VERSION ""

NS_ :

BS_:

BU_: XXX

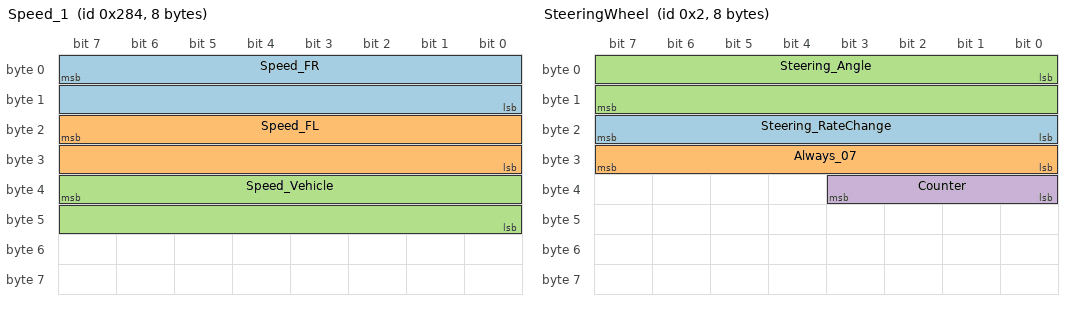
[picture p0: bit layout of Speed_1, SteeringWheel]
BO_ 644 Speed_1: 8 XXX
 SG_ Speed_FR : 7|16@0+ (0.0118,0) [0|65535] "" XXX
 SG_ Speed_FL : 23|16@0+ (0.0118,0) [0|65535] "" XXX
 SG_ Speed_Vehicle : 39|16@0+ (0.0245,0) [0|65535] "" XXX

BO_ 645 WheelspeedRear: 8 XXX
 SG_ RR : 7|16@0+ (0.00555,0) [0|65535] "KPH" XXX
 SG_ RL : 23|16@0+ (0.00555,0) [0|65535] "KPH" XXX

BO_ 768 STEER_TORQUE: 2 XXX
 SG_ STEERING_TORQUE : 6|7@0+ (1,0) [0|127] "" XXX
 SG_ DriverTouchingWheel : 15|1@0+ (-1,1) [0|7] "" XXX

BO_ 459 Maybe_RegenBraking: 8 XXX

BO_ 372 Maybe_Gear_Selector: 8 XXX
 SG_ Counter : 35|4@0+ (1,0) [0|15] "" XXX

BO_ 374 Maybe_Motor_RPM_or_Speed: 8 XXX
 SG_ Counter : 51|4@0+ (1,0) [0|15] "" XXX

BO_ 460 Maybe_Brake_Related: 8 XXX

BO_ 2 SteeringWheel: 8 XXX
 SG_ Steering_RateChange : 16|8@1+ (1,0) [0|255] "" XXX
 SG_ Always_07 : 24|8@1+ (1,0) [0|255] "" XXX
 SG_ Steering_Angle : 0|16@1- (-0.1,0) [0|65535] "" XXX
 SG_ Counter : 32|4@1+ (1,0) [0|15] "" XXX

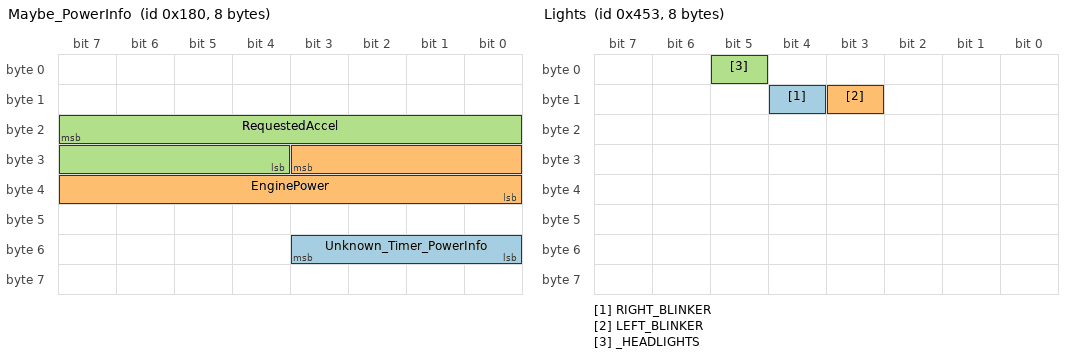
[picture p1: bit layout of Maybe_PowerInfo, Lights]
BO_ 384 Maybe_PowerInfo: 8 XXX
 SG_ Unknown_Timer_PowerInfo : 51|4@0+ (1,0) [0|15] "" XXX
 SG_ EnginePower : 27|12@0- (1,0) [0|1] "" XXX
 SG_ RequestedAccel : 23|12@0- (1,0) [0|4294967295] "" XXX

BO_ 1107 Lights: 8 XXX
 SG_ RIGHT_BLINKER : 12|1@0+ (1,0) [0|1] "" XXX
 SG_ LEFT_BLINKER : 11|1@0+ (1,0) [0|1] "" XXX
 SG_ _HEADLIGHTS : 5|1@0+ (1,0) [0|1] "" XXX

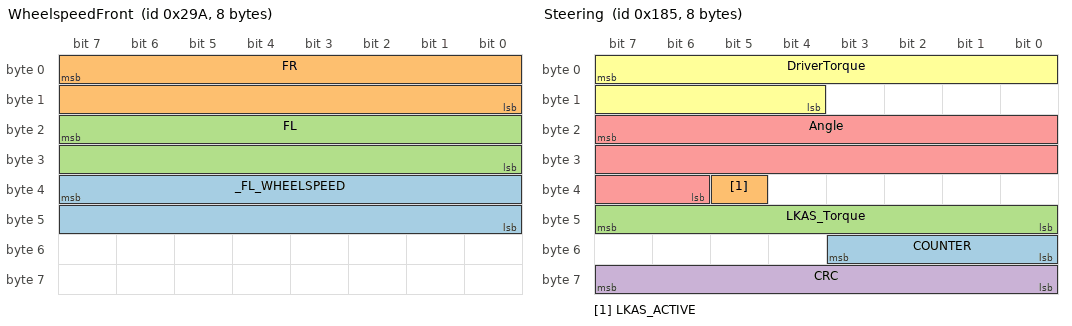
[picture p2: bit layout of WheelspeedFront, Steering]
BO_ 666 WheelspeedFront: 8 XXX
 SG_ _FL_WHEELSPEED : 39|16@0+ (0.01014,0) [0|65535] "" XXX
 SG_ FR : 7|16@0+ (0.00555,0) [0|65535] "KPH" XXX
 SG_ FL : 23|16@0+ (0.00555,0) [0|65535] "KPH" XXX

BO_ 389 Steering: 8 XXX
 SG_ COUNTER : 51|4@0+ (1,0) [0|15] "" XXX
 SG_ LKAS_ACTIVE : 37|1@0+ (1,0) [0|3] "" XXX
 SG_ LKAS_Torque : 47|8@0+ (1,0) [0|255] "" XXX
 SG_ CRC : 63|8@0+ (1,0) [0|127] "" XXX
 SG_ Angle : 23|18@0+ (-0.01,1310) [0|262143] "" XXX
 SG_ DriverTorque : 7|12@0+ (-0.01,20.47) [0|4095] "Nm" XXX

BO_ 851 SPEED_RELATED: 8 XXX
 SG_ SPEED_RELATED : 7|16@0+ (0.01014,0) [0|65535] "" XXX

BO_ 386 Accelerator: 8 XXX
 SG_ Accelerator : 38|7@0+ (1,0) [0|127] "" XXX

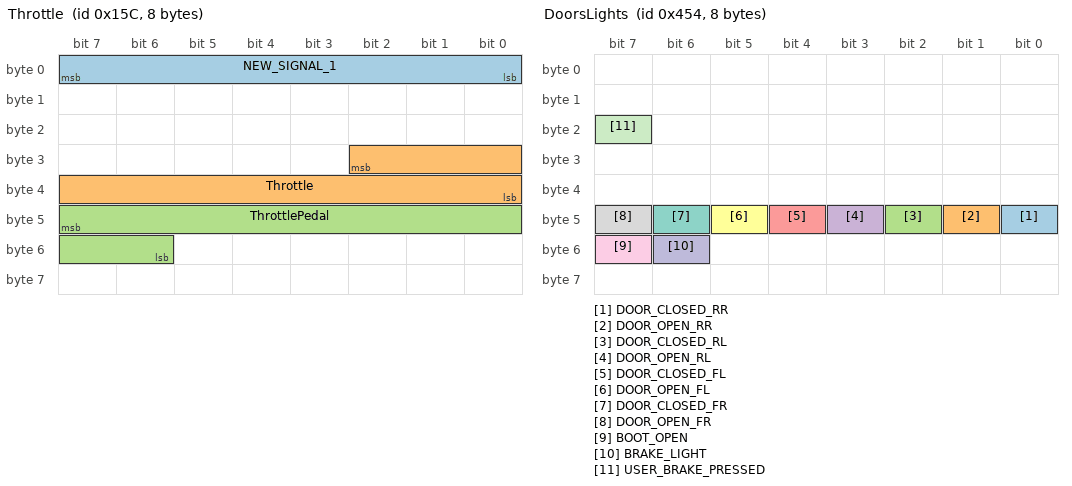
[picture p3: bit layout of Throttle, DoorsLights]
BO_ 348 Throttle: 8 XXX
 SG_ NEW_SIGNAL_1 : 7|8@0+ (1,0) [0|255] "" XXX
 SG_ Throttle : 26|11@0+ (1,0) [0|2047] "" XXX
 SG_ ThrottlePedal : 47|10@0+ (1,0) [0|1023] "" XXX

BO_ 523 CruiseThrottle: 6 XXX
 SG_ PROPILOT_BUTTON : 8|1@0+ (1,0) [0|1] "" XXX
 SG_ CANCEL_BUTTON : 9|1@0+ (1,0) [0|1] "" XXX
 SG_ GAS_PEDAL_INVERTED : 37|10@0+ (1,0) [0|1023] "" XXX
 SG_ SET_BUTTON : 11|1@0+ (1,0) [0|1] "" XXX
 SG_ RES_BUTTON : 12|1@0+ (1,0) [0|1] "" XXX
 SG_ FOLLOW_DISTANCE_BUTTON : 10|1@0+ (1,0) [0|1] "" XXX
 SG_ NO_BUTTON_PRESSED : 13|1@0+ (1,0) [0|1] "" XXX
 SG_ GAS_PEDAL : 31|10@0+ (1,0) [0|255] "" XXX
 SG_ USER_BRAKE_PRESSED : 21|1@0+ (1,0) [0|1] "" XXX
 SG_ USER_BRAKE_PRESSED_INVERTED : 22|1@0+ (1,0) [0|3] "" XXX
 SG_ NEW_SIGNAL_2 : 23|1@0+ (1,0) [0|1] "" XXX
 SG_ unsure2 : 43|4@0+ (1,0) [0|1] "" XXX
 SG_ unsure1 : 7|16@0+ (1,0) [0|15] "" XXX
 SG_ GAS_PRESSED_INVERTED : 20|1@0+ (1,0) [0|255] "" XXX
 SG_ COUNTER : 17|2@0+ (1,0) [0|3] "" XXX
 SG_ unsure3 : 19|2@0+ (1,0) [0|3] "" XXX

BO_ 1108 DoorsLights: 8 XXX
 SG_ DOOR_CLOSED_RR : 40|1@0+ (1,0) [0|1] "" XXX
 SG_ DOOR_OPEN_RR : 41|1@0+ (1,0) [0|1] "" XXX
 SG_ DOOR_CLOSED_RL : 42|1@0+ (1,0) [0|1] "" XXX
 SG_ DOOR_OPEN_RL : 43|1@0+ (1,0) [0|1] "" XXX
 SG_ DOOR_CLOSED_FL : 44|1@0+ (1,0) [0|1] "" XXX
 SG_ DOOR_OPEN_FL : 45|1@0+ (1,0) [0|1] "" XXX
 SG_ DOOR_CLOSED_FR : 46|1@0+ (1,0) [0|3] "" XXX
 SG_ DOOR_OPEN_FR : 47|1@0+ (1,0) [0|3] "" XXX
 SG_ BOOT_OPEN : 55|1@0+ (1,0) [0|1] "" XXX
 SG_ BRAKE_LIGHT : 54|1@0+ (1,0) [0|1] "" XXX
 SG_ USER_BRAKE_PRESSED : 23|1@0+ (1,0) [0|1] "" XXX

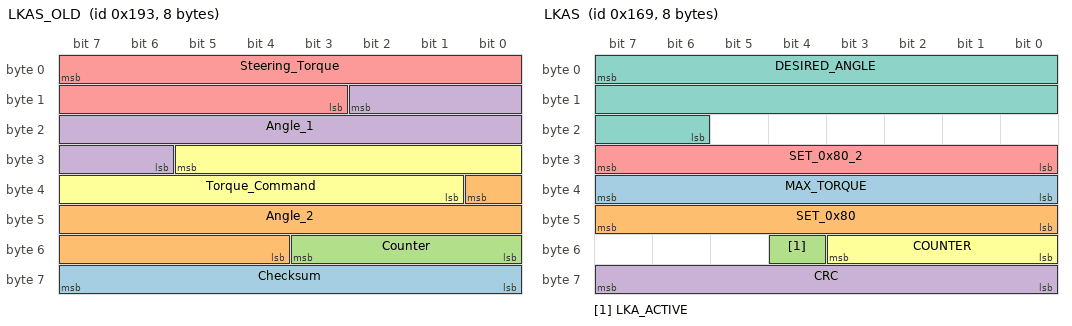
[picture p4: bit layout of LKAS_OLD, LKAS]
BO_ 403 LKAS_OLD: 8 XXX
 SG_ Checksum : 63|8@0+ (1,0) [0|255] "" XXX
 SG_ Angle_2 : 32|13@0+ (1,-4000) [0|63] "" XXX
 SG_ Counter : 51|4@0+ (1,0) [0|15] "" XXX
 SG_ Angle_1 : 10|13@0+ (0.12,-480) [0|65535] "" XXX
 SG_ Steering_Torque : 7|13@0+ (-1,4000) [0|65535] "" XXX
 SG_ Torque_Command : 29|13@0+ (1,-4000) [0|255] "" XXX

BO_ 361 LKAS: 8 XXX
 SG_ MAX_TORQUE : 39|8@0+ (0.01,0) [0|255] "Nm" XXX
 SG_ SET_0x80 : 47|8@0+ (1,0) [0|255] "" XXX
 SG_ LKA_ACTIVE : 52|1@0+ (1,0) [0|15] "" XXX
 SG_ CRC : 63|8@0+ (1,0) [0|255] "" XXX
 SG_ SET_0x80_2 : 31|8@0+ (1,0) [0|255] "" XXX
 SG_ COUNTER : 51|4@0+ (1,0) [0|15] "" XXX
 SG_ DESIRED_ANGLE : 7|18@0+ (-0.01,1310) [0|255] "" XXX

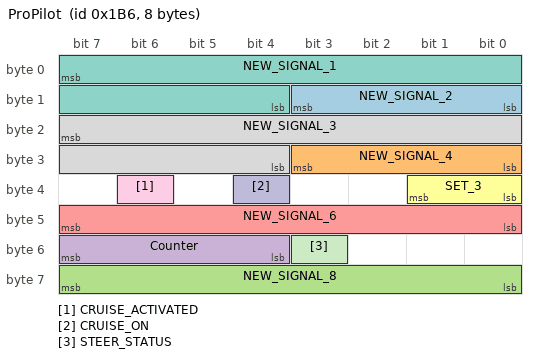
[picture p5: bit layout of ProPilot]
BO_ 438 ProPilot: 8 XXX
 SG_ NEW_SIGNAL_2 : 11|4@0+ (1,0) [0|255] "" XXX
 SG_ NEW_SIGNAL_4 : 27|4@0+ (1,0) [0|255] "" XXX
 SG_ NEW_SIGNAL_8 : 63|8@0+ (1,0) [0|7] "" XXX
 SG_ Counter : 55|4@0+ (1,0) [0|255] "" XXX
 SG_ NEW_SIGNAL_6 : 47|8@0+ (1,0) [0|255] "" XXX
 SG_ SET_3 : 33|2@0+ (1,0) [0|15] "" XXX
 SG_ NEW_SIGNAL_1 : 7|12@0- (1,0) [0|255] "" XXX
 SG_ NEW_SIGNAL_3 : 23|12@0- (-1,0) [0|255] "" XXX
 SG_ CRUISE_ACTIVATED : 38|1@0+ (1,0) [0|3] "" XXX
 SG_ CRUISE_ON : 36|1@0+ (1,0) [0|255] "" XXX
 SG_ STEER_STATUS : 51|1@0+ (1,0) [0|3] "" XXX

BO_ 397 _GEAR: 8 XXX
 SG_ GEAR : 27|4@0+ (1,0) [0|15] "" XXX

BO_ 1273 _SEATBELT: 7 XXX
 SG_ DRIVERS_SEATBELT : 25|1@0+ (1,0) [0|1] "" XXX

BO_ 665 _ESP: 8 XXX
 SG_ ESP_DISABLED : 24|1@0+ (1,0) [0|1] "" XXX

BO_ 1055 GEARBOX: 2 XXX
 SG_ SPORTS_MODE : 13|1@0+ (1,0) [0|1] "" XXX
 SG_ GEAR_SHIFTER : 5|3@0+ (1,0) [0|255] "" XXX

BO_ 1228 PROPILOT_HUD_INFO_MSG: 8 XXX
 SG_ NA_HIGH_ACCEL_TEMP : 0|1@0+ (1,0) [0|1] "" XXX
 SG_ SIDE_RADAR_NA_HIGH_CABIN_TEMP : 8|1@0+ (1,0) [0|1] "" XXX
 SG_ SIDE_RADAR_MALFUNCTION : 11|1@0+ (1,0) [0|1] "" XXX
 SG_ LKAS_MALFUNCTION : 12|1@0+ (1,0) [0|1] "" XXX
 SG_ FRONT_RADAR_MALFUNCTION : 13|1@0+ (1,0) [0|1] "" XXX
 SG_ SIDE_RADAR_NA_CLEAN_REAR_CAMERA : 14|1@0+ (1,0) [0|1] "" XXX
 SG_ NA_POOR_ROAD_CONDITIONS : 16|1@0+ (1,0) [0|1] "" XXX
 SG_ CURRENTLY_UNAVAILABLE : 17|1@0+ (1,0) [0|1] "" XXX
 SG_ SAFETY_SHIELD_OFF : 18|1@0+ (1,0) [0|1] "" XXX
 SG_ FRONT_COLLISION_NA_FRONT_RADAR_OBSTRUCTION : 20|1@0+ (1,0) [0|1] "" XXX
 SG_ PEDAL_MISSAPPLICATION_SYSTEM_ACTIVATED : 24|1@0+ (1,0) [0|1] "" XXX
 SG_ SIDE_IMPACT_NA_RADAR_OBSTRUCTION : 25|1@0+ (1,0) [0|1] "" XXX
 SG_ WARNING_DO_NOT_ENTER : 33|1@0+ (1,0) [0|1] "" XXX
 SG_ SIDE_IMPACT_SYSTEM_OFF : 34|1@0+ (1,0) [0|1] "" XXX
 SG_ SIDE_IMPACT_MALFUNCTION : 35|1@0+ (1,0) [0|1] "" XXX
 SG_ FRONT_COLLISION_MALFUNCTION : 36|1@0+ (1,0) [0|1] "" XXX
 SG_ SIDE_RADAR_MALFUNCTION2 : 37|1@0+ (1,0) [0|1] "" XXX
 SG_ LKAS_MALFUNCTION2 : 38|1@0+ (1,0) [0|1] "" XXX
 SG_ FRONT_RADAR_MALFUNCTION2 : 39|1@0+ (1,0) [0|1] "" XXX
 SG_ PROPILOT_NA_MSGS : 42|3@0+ (1,0) [0|7] "" XXX
 SG_ BOTTOM_MSG : 45|3@0+ (1,0) [0|7] "" XXX
 SG_ HANDS_ON_WHEEL_WARNING : 47|1@0+ (1,0) [0|1] "" XXX
 SG_ WARNING_STEP_ON_BRAKE_NOW : 51|1@0+ (1,0) [0|1] "" XXX
 SG_ PROPILOT_NA_FRONT_CAMERA_OBSTRUCTED : 52|1@0+ (1,0) [0|1] "" XXX
 SG_ PROPILOT_NA_HIGH_CABIN_TEMP : 53|1@0+ (1,0) [0|1] "" XXX
 SG_ WARNING_PROPILOT_MALFUNCTION : 54|1@0+ (1,0) [0|3] "" XXX
 SG_ ACC_UNAVAILABLE_HIGH_CABIN_TEMP : 62|1@0+ (1,0) [0|1] "" XXX
 SG_ ACC_NA_FRONT_CAMERA_IMPARED : 63|1@0+ (1,0) [0|1] "" XXX
 SG_ unknown07 : 7|7@0+ (1,0) [0|127] "" XXX
 SG_ unknown10 : 10|2@0+ (1,0) [0|3] "" XXX
 SG_ unknown15 : 15|1@0+ (1,0) [0|1] "" XXX
 SG_ unknown23 : 23|3@0+ (1,0) [0|7] "" XXX
 SG_ unknown19 : 19|1@0+ (1,0) [0|1] "" XXX
 SG_ unknown31 : 31|6@0+ (1,0) [0|63] "" XXX
 SG_ unknown32 : 32|1@0+ (1,0) [0|1] "" XXX
 SG_ unknown46 : 46|1@0+ (1,0) [0|1] "" XXX
 SG_ unknown61 : 61|6@0+ (1,0) [0|63] "" XXX
 SG_ unknown55 : 55|1@0+ (1,0) [0|1] "" XXX
 SG_ unknown50 : 50|3@0+ (1,0) [0|7] "" XXX

BO_ 689 PROPILOT_HUD: 8 XXX
 SG_ LARGE_WARNING_FLASHING : 9|1@0+ (1,0) [0|1] "" XXX
 SG_ SIDE_RADAR_ERROR_FLASHING1 : 10|1@0+ (1,0) [0|1] "" XXX
 SG_ SIDE_RADAR_ERROR_FLASHING2 : 11|1@0+ (1,0) [0|1] "" XXX
 SG_ RIGHT_LANE_YELLOW_FLASH : 12|1@0+ (1,0) [0|1] "" XXX
 SG_ LEFT_LANE_YELLOW_FLASH : 13|1@0+ (1,0) [0|1] "" XXX
 SG_ LEAD_CAR : 14|1@0+ (1,0) [0|1] "" XXX
 SG_ LEAD_CAR_ERROR : 15|1@0+ (1,0) [0|1] "" XXX
 SG_ FRONT_RADAR_ERROR : 16|1@0+ (1,0) [0|1] "" XXX
 SG_ FRONT_RADAR_ERROR_FLASHING : 17|1@0+ (1,0) [0|1] "" XXX
 SG_ RIGHT_LANE_GREEN : 24|1@0+ (1,0) [0|1] "" XXX
 SG_ LEFT_LANE_GREEN : 25|1@0+ (1,0) [0|1] "" XXX
 SG_ SIDE_RADAR_ERROR_FLASHING3 : 27|1@0+ (1,0) [0|1] "" XXX
 SG_ LKAS_ERROR_FLASHING : 29|1@0+ (1,0) [0|1] "" XXX
 SG_ SAFETY_SHIELD_ACTIVE : 44|1@0+ (1,0) [0|1] "" XXX
 SG_ LARGE_STEERING_WHEEL_ICON : 61|2@0+ (1,0) [0|3] "" XXX
 SG_ RIGHT_LANE_GREEN_FLASH : 62|1@0+ (1,0) [0|1] "" XXX
 SG_ LEFT_LANE_GREEN_FLASH : 63|1@0+ (1,0) [0|1] "" XXX
 SG_ FOLLOW_DISTANCE : 3|2@0+ (1,0) [0|3] "" XXX
 SG_ AUDIBLE_TONE : 47|3@0+ (1,0) [0|8] "" XXX
 SG_ SPEED_SET_ICON : 7|2@0+ (1,0) [0|3] "" XXX
 SG_ SMALL_STEERING_WHEEL_ICON : 42|3@0+ (1,0) [0|7] "" XXX
 SG_ unknown59 : 59|4@0+ (1,0) [0|15] "" XXX
 SG_ unknown55 : 55|8@0+ (1,0) [0|63] "" XXX
 SG_ unknown26 : 26|1@0+ (1,0) [0|1] "" XXX
 SG_ unknown28 : 28|1@0+ (1,0) [0|1] "" XXX
 SG_ unknown31 : 31|2@0+ (1,0) [0|3] "" XXX
 SG_ unknown39 : 39|8@0+ (1,0) [0|255] "" XXX
 SG_ unknown43 : 43|1@0+ (1,0) [0|1] "" XXX
 SG_ unknown8 : 8|7@0+ (1,0) [0|63] "" XXX
 SG_ unknown05 : 5|2@0+ (1,0) [0|3] "" XXX
 SG_ unknown02 : 1|2@0+ (1,0) [0|3] "" XXX

VAL_ 1055 GEAR_SHIFTER 6 "L" 4 "D" 3 "N" 2 "R" 1 "P" ;
VAL_ 1228 PROPILOT_NA_MSGS 0 "NO_MSG" 1 "NA_FRONT_CAMERA_IMPARED" 2 "STEERING_ASSIST_ON_STANDBY" 3 "NA_PARKING_ASSIST_ENABLED" 4 "STEER_ASSIST_CURRENTLY_NA" 5 "NA_BAD_WEATHER" 6 "NA_PARK_BRAKE_ON" 7 "NA_SEATBELT_NOT_FASTENED" ;
VAL_ 1228 BOTTOM_MSG 0 "OK_STEER_ASSIST_SETTINGS" 1 "NO_MSG" 2 "PRESS_SET_TO_SET_SPEED" 3 "PRESS_RES_SET_TO_CHANGE_SPEED" 4 "PRESS_RES_TO_RESTART" 5 "NO_MSG" 6 "CRUISE_NOT_AVAIL" 7 "NO_MSG" ;
VAL_ 689 FOLLOW_DISTANCE 0 "NO_FOLLOW_DISTANCE" 1 "FOLLOW_DISTANCE_1" 2 "FOLLOW_DISTANCE_2" 3 "FOLLOW_DISANCE_3" ;
VAL_ 689 AUDIBLE_TONE 0 "NO_TONE" 1 "CONT" 2 "FAST_BEEP_CONT" 3 "TRIPLE_FAST_BEEP_CONT" 4 "SLOW_BEEP_CONT" 5 "QUAD_SLOW_BEEP_CONT" 6 "SINGLE_BEEP_ONCE" 7 "DOUBLE_BEEP_ONCE" ;
VAL_ 689 SMALL_STEERING_WHEEL_ICON 0 "NO_ICON" 1 "GRAY_ICON" 2 "GRAY_ICON_FLASHING" 3 "GREEN_ICON" 4 "GREEN_ICON_FLASHING" 5 "RED_ICON" 6 "RED_ICON_FLASHING" 7 "YELLOW_ICON" ;
VAL_ 689 LARGE_STEERING_WHEEL_ICON 0 "NO_STEERINGWHEEL" 1 "GRAY_STEERINGWHEEL" 2 "GREEN_STEERINGWHEEL" 3 "GREEN_STEERINGWHEEL_FLASHING" ;
